VERSION ""

NS_ :

BS_:

BU_:

CM_ "(*  NOTICE: This is a sample DBC file for educational purposes only. It is not  intended for use in any production or commercial application. The content  of this file is based on the J1939 DBC format, which is a standard for  communication between electronic control units (ECUs) in heavy-duty  vehicles. The J1939 DBC format is a proprietary standard developed by the  Society of Automotive Engineers (SAE) and is subject to copyright and  licensing restrictions.";

BO_ 2565935153 B2: 8 Vector__XXX
 SG_ B2_Brake_Switch_2 : 16|2@1+ (1,0) [0|3] "" Vector__XXX
 SG_ B2_Demanded_Brake_Pres : 0|16@1+ (0.1,0) [0|0] "kPa" Vector__XXX

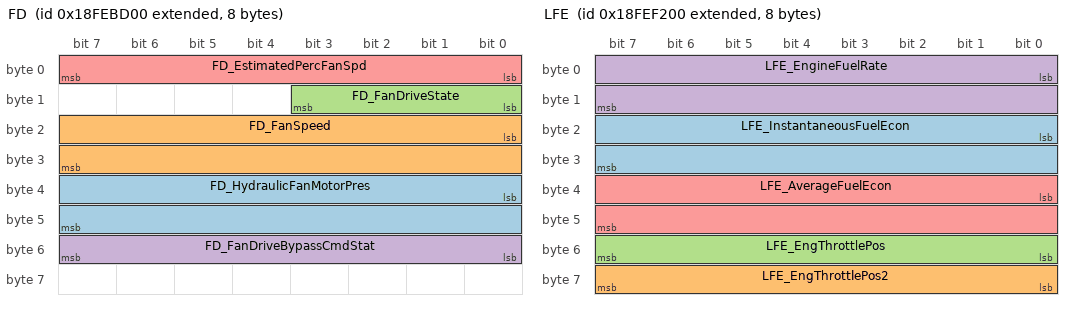
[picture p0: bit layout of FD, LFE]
BO_ 2566831360 FD: 8 Vector__XXX
 SG_ FD_HydraulicFanMotorPres : 32|16@1+ (0.5,0) [0|32127.5] "kPa" Vector__XXX
 SG_ FD_FanSpeed : 16|16@1+ (0.125,0) [0|8031.75] "rpm" Vector__XXX
 SG_ FD_FanDriveState : 8|4@1+ (1,0) [0|15] "bit" Vector__XXX
 SG_ FD_FanDriveBypassCmdStat : 48|8@1+ (0.4,0) [0|100] "%" Vector__XXX
 SG_ FD_EstimatedPercFanSpd : 0|8@1+ (0.4,0) [0|100] "%" Vector__XXX

BO_ 2566719744 HRLCF: 8 Vector__XXX
 SG_ HRLCF_EngineTripFuelHighRes : 0|32@1+ (0.001,0) [0|4211081.215] "L" Vector__XXX
 SG_ HRLCF_EngineTotalFuelUsedHighRes : 32|32@1+ (0.001,0) [0|4211081.215] "L" Vector__XXX

BO_ 2566842624 LFC: 8 Vector__XXX
 SG_ LFC_EngineTripFuel : 0|32@1+ (0.5,0) [0|2105540607.5] "L" Vector__XXX
 SG_ LFC_EngineTotalFuelUsed : 32|32@1+ (0.5,0) [0|2105540607.5] "L" Vector__XXX

BO_ 2566844928 LFE: 8 Vector__XXX
 SG_ LFE_InstantaneousFuelEcon : 16|16@1+ (0.001953125,0) [0|125.5] "km/l" Vector__XXX
 SG_ LFE_EngThrottlePos2 : 56|8@1+ (0.4,0) [0|100] "%" Vector__XXX
 SG_ LFE_EngThrottlePos : 48|8@1+ (0.4,0) [0|100] "%" Vector__XXX
 SG_ LFE_EngineFuelRate : 0|16@1+ (0.05,0) [0|3212.75] "L/h" Vector__XXX
 SG_ LFE_AverageFuelEcon : 32|16@1+ (0.001953125,0) [0|125.5] "km/l" Vector__XXX

BO_ 2566832384 VDHR: 8 Vector__XXX
 SG_ VDHR_TotalVehicleDistance : 0|32@1+ (5,0) [0|21055406] "m" Vector__XXX
 SG_ VDHR_TotalTripDistance : 32|32@1+ (5,0) [0|21055406] "m" Vector__XXX

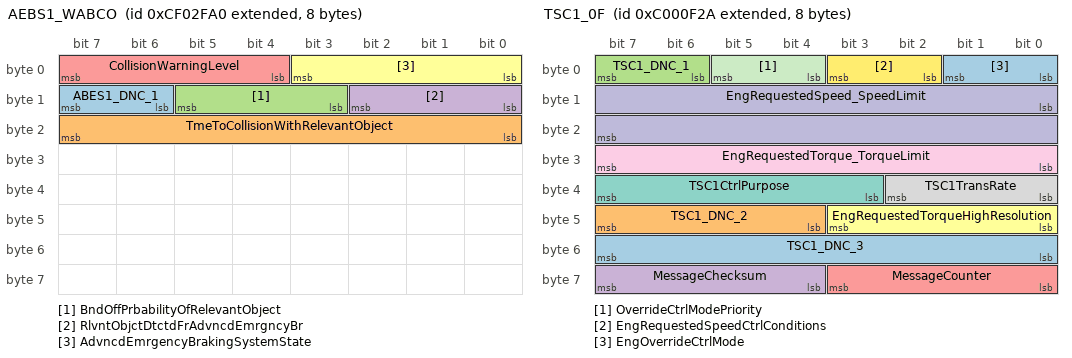
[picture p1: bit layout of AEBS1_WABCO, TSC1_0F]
BO_ 2364551072 AEBS1_WABCO: 8 Vector__XXX
 SG_ ABES1_DNC_1 : 14|2@1+ (1,0) [0|3] "" Vector__XXX
 SG_ TmeToCollisionWithRelevantObject : 16|8@1+ (0.05,0) [0|12.5] "s" Vector__XXX
 SG_ BndOffPrbabilityOfRelevantObject : 11|3@1+ (1,0) [0|7] "" Vector__XXX
 SG_ RlvntObjctDtctdFrAdvncdEmrgncyBr : 8|3@1+ (1,0) [0|7] "" Vector__XXX
 SG_ CollisionWarningLevel : 4|4@1+ (1,0) [0|15] "" Vector__XXX
 SG_ AdvncdEmrgencyBrakingSystemState : 0|4@1+ (1,0) [0|15] "" Vector__XXX

BO_ 2365518080 CCVS1_FW: 8 Vector__XXX
 SG_ EngShutdownOverrideSwitch : 62|2@1+ (1,0) [0|3] "" Vector__XXX
 SG_ EngTestModeSwitch : 60|2@1+ (1,0) [0|3] "" Vector__XXX
 SG_ EngIdleDecrementSwitch : 58|2@1+ (1,0) [0|3] "" Vector__XXX
 SG_ EngIdleIncrementSwitch : 56|2@1+ (1,0) [0|3] "" Vector__XXX
 SG_ CruiseCtrlStates : 53|3@1+ (1,0) [0|7] "" Vector__XXX
 SG_ PTOGovernorState : 48|5@1+ (1,0) [0|31] "" Vector__XXX
 SG_ CruiseCtrlSetSpeed : 40|8@1+ (1,0) [0|250] "km/h" Vector__XXX
 SG_ CruiseCtrlAccelerateSwitch : 38|2@1+ (1,0) [0|3] "" Vector__XXX
 SG_ CruiseCtrlResumeSwitch : 36|2@1+ (1,0) [0|3] "" Vector__XXX
 SG_ CruiseCtrlCoastSwitch : 34|2@1+ (1,0) [0|3] "" Vector__XXX
 SG_ CruiseCtrlSetSwitch : 32|2@1+ (1,0) [0|3] "" Vector__XXX
 SG_ ClutchSwitch : 30|2@1+ (1,0) [0|3] "" Vector__XXX
 SG_ BrakeSwitch : 28|2@1+ (1,0) [0|3] "" Vector__XXX
 SG_ CruiseCtrlEnableSwitch : 26|2@1+ (1,0) [0|3] "" Vector__XXX
 SG_ CruiseCtrlActive : 24|2@1+ (1,0) [0|3] "" Vector__XXX
 SG_ WheelBasedVehicleSpeed : 8|16@1+ (0.00390625,0) [0|250.996] "km/h" Vector__XXX
 SG_ ParkBrakeReleaseInhibitRq : 6|2@1+ (1,0) [0|3] "" Vector__XXX
 SG_ CruiseCtrlPauseSwitch : 4|2@1+ (1,0) [0|3] "" Vector__XXX
 SG_ ParkingBrakeSwitch : 2|2@1+ (1,0) [0|3] "" Vector__XXX
 SG_ TwoSpeedAxleSwitch : 0|2@1+ (1,0) [0|3] "" Vector__XXX

BO_ 2348814122 TSC1_0F: 8 Vector__XXX
 SG_ TSC1_DNC_3 : 48|8@1+ (1,0) [0|255] "" Vector__XXX
 SG_ TSC1_DNC_2 : 44|4@1+ (1,0) [0|15] "" Vector__XXX
 SG_ TSC1_DNC_1 : 6|2@1+ (1,0) [0|3] "" Vector__XXX
 SG_ MessageChecksum : 60|4@1+ (1,0) [0|15] "" Vector__XXX
 SG_ MessageCounter : 56|4@1+ (1,0) [0|15] "" Vector__XXX
 SG_ EngRequestedTorqueHighResolution : 40|4@1+ (0.125,0) [0|1.875] "%" Vector__XXX
 SG_ TSC1CtrlPurpose : 35|5@1+ (1,0) [0|31] "" Vector__XXX
 SG_ TSC1TransRate : 32|3@1+ (1,0) [0|7] "" Vector__XXX
 SG_ EngRequestedTorque_TorqueLimit : 24|8@1+ (1,-125) [-125|125] "%" Vector__XXX
 SG_ EngRequestedSpeed_SpeedLimit : 8|16@1+ (0.125,0) [0|8031.875] "rpm" Vector__XXX
 SG_ OverrideCtrlModePriority : 4|2@1+ (1,0) [0|3] "" Vector__XXX
 SG_ EngRequestedSpeedCtrlConditions : 2|2@1+ (1,0) [0|3] "" Vector__XXX
 SG_ EngOverrideCtrlMode : 0|2@1+ (1,0) [0|3] "" Vector__XXX

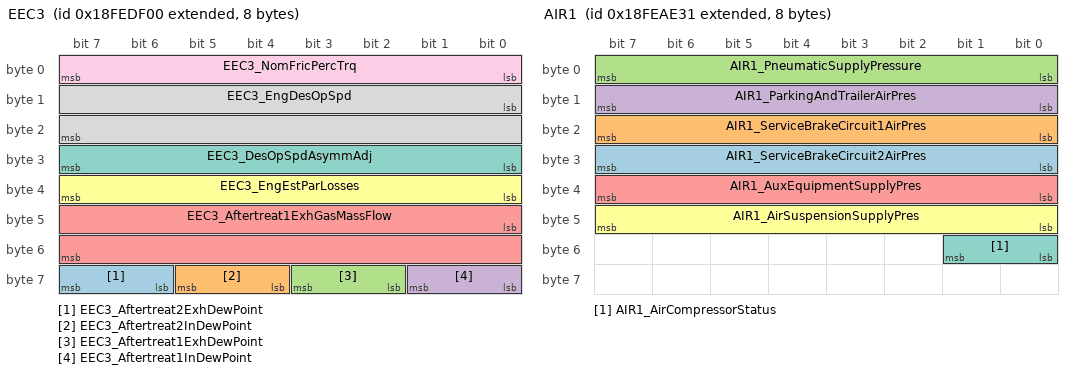
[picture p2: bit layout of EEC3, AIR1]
BO_ 2566840064 EEC3: 8 Vector__XXX
 SG_ EEC3_Aftertreat2ExhDewPoint : 62|2@1+ (1,0) [0|3] "bit" Vector__XXX
 SG_ EEC3_Aftertreat2InDewPoint : 60|2@1+ (1,0) [0|3] "bit" Vector__XXX
 SG_ EEC3_Aftertreat1ExhDewPoint : 58|2@1+ (1,0) [0|3] "bit" Vector__XXX
 SG_ EEC3_Aftertreat1InDewPoint : 56|2@1+ (1,0) [0|3] "bit" Vector__XXX
 SG_ EEC3_Aftertreat1ExhGasMassFlow : 40|16@1+ (0.2,0) [0|12851] "kg/h" Vector__XXX
 SG_ EEC3_EngEstParLosses : 32|8@1+ (1,-125) [-125|125] "%" Vector__XXX
 SG_ EEC3_DesOpSpdAsymmAdj : 24|8@1+ (1,0) [0|250] "-" Vector__XXX
 SG_ EEC3_EngDesOpSpd : 8|16@1+ (0.125,0) [0|8031.875] "rpm" Vector__XXX
 SG_ EEC3_NomFricPercTrq : 0|8@1+ (1,-125) [-125|125] "%" Vector__XXX

BO_ 2566827569 AIR1: 8 Vector__XXX
 SG_ AIR1_ServiceBrakeCircuit2AirPres : 24|8@1+ (1.1603,0) [0|290] "psi" Vector__XXX
 SG_ AIR1_ServiceBrakeCircuit1AirPres : 16|8@1+ (1.1603,0) [0|290] "psi" Vector__XXX
 SG_ AIR1_PneumaticSupplyPressure : 0|8@1+ (1.1603,0) [0|290] "psi" Vector__XXX
 SG_ AIR1_ParkingAndTrailerAirPres : 8|8@1+ (1.1603,0) [0|290] "psi" Vector__XXX
 SG_ AIR1_AuxEquipmentSupplyPres : 32|8@1+ (1.1603,0) [0|290] "psi" Vector__XXX
 SG_ AIR1_AirSuspensionSupplyPres : 40|8@1+ (1.1603,0) [0|290] "psi" Vector__XXX
 SG_ AIR1_AirCompressorStatus : 48|2@1+ (1,0) [0|3] "bit" Vector__XXX

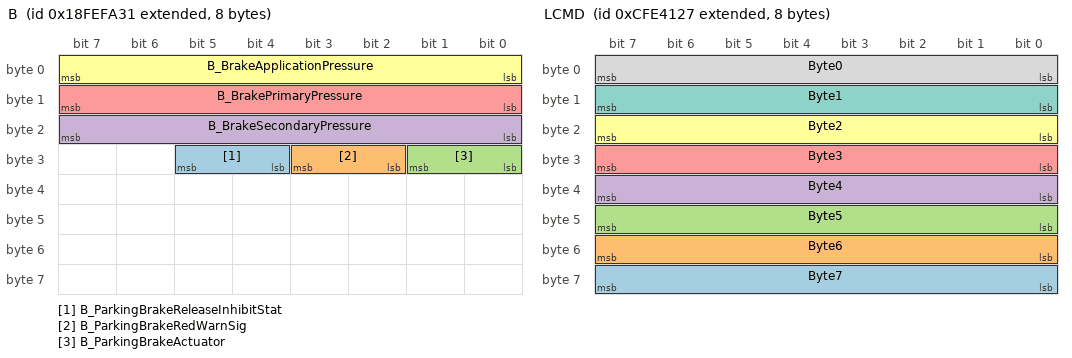
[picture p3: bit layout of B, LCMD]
BO_ 2566847025 B: 8 Vector__XXX
 SG_ B_ParkingBrakeReleaseInhibitStat : 28|2@1+ (1,0) [0|3] "bit" Vector__XXX
 SG_ B_ParkingBrakeRedWarnSig : 26|2@1+ (1,0) [0|3] "bit" Vector__XXX
 SG_ B_ParkingBrakeActuator : 24|2@1+ (1,0) [0|3] "bit" Vector__XXX
 SG_ B_BrakeSecondaryPressure : 16|8@1+ (4,0) [0|1000] "kPa" Vector__XXX
 SG_ B_BrakePrimaryPressure : 8|8@1+ (4,0) [0|1000] "kPa" Vector__XXX
 SG_ B_BrakeApplicationPressure : 0|8@1+ (4,0) [0|1000] "kPa" Vector__XXX

BO_ 2365473063 LCMD: 8 Vector__XXX
 SG_ Byte7 : 56|8@1+ (1,0) [0|255] "" Vector__XXX
 SG_ Byte6 : 48|8@1+ (1,0) [0|255] "" Vector__XXX
 SG_ Byte5 : 40|8@1+ (1,0) [0|255] "" Vector__XXX
 SG_ Byte4 : 32|8@1+ (1,0) [0|255] "" Vector__XXX
 SG_ Byte3 : 24|8@1+ (1,0) [0|255] "" Vector__XXX
 SG_ Byte2 : 16|8@1+ (1,0) [0|255] "" Vector__XXX
 SG_ Byte1 : 8|8@1+ (1,0) [0|255] "" Vector__XXX
 SG_ Byte0 : 0|8@1+ (1,0) [0|255] "" Vector__XXX

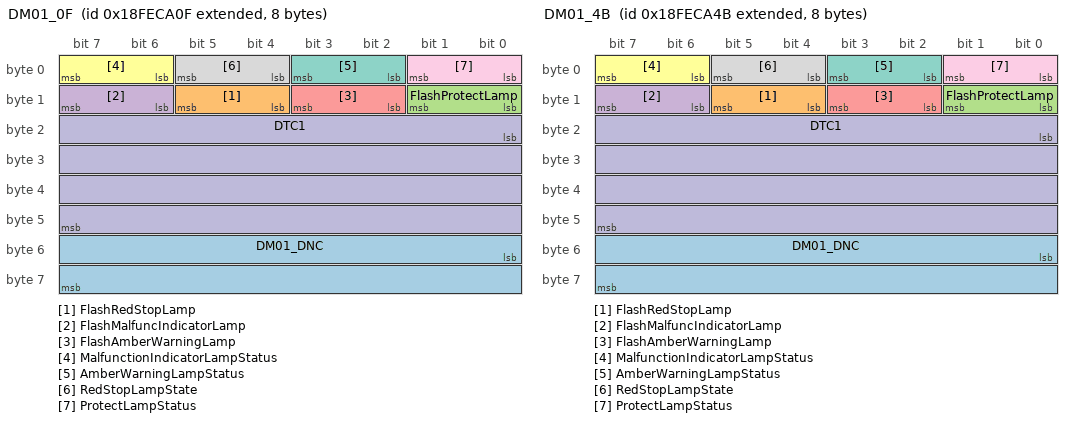
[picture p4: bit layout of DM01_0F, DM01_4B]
BO_ 2566834703 DM01_0F: 8 Vector__XXX
 SG_ DM01_DNC : 48|16@1+ (1,0) [0|0] "" Vector__XXX
 SG_ FlashRedStopLamp : 12|2@1+ (1,0) [0|3] "" Vector__XXX
 SG_ FlashProtectLamp : 8|2@1+ (1,0) [0|3] "" Vector__XXX
 SG_ FlashMalfuncIndicatorLamp : 14|2@1+ (1,0) [0|3] "" Vector__XXX
 SG_ FlashAmberWarningLamp : 10|2@1+ (1,0) [0|3] "" Vector__XXX
 SG_ MalfunctionIndicatorLampStatus : 6|2@1+ (1,0) [0|3] "" Vector__XXX
 SG_ AmberWarningLampStatus : 2|2@1+ (1,0) [0|3] "" Vector__XXX
 SG_ RedStopLampState : 4|2@1+ (1,0) [0|3] "" Vector__XXX
 SG_ ProtectLampStatus : 0|2@1+ (1,0) [0|3] "" Vector__XXX
 SG_ DTC1 : 16|32@1+ (1,0) [0|4294967295] "" Vector__XXX

BO_ 2566834763 DM01_4B: 8 Vector__XXX
 SG_ DM01_DNC : 48|16@1+ (1,0) [0|0] "" Vector__XXX
 SG_ FlashRedStopLamp : 12|2@1+ (1,0) [0|3] "" Vector__XXX
 SG_ FlashProtectLamp : 8|2@1+ (1,0) [0|3] "" Vector__XXX
 SG_ FlashMalfuncIndicatorLamp : 14|2@1+ (1,0) [0|3] "" Vector__XXX
 SG_ FlashAmberWarningLamp : 10|2@1+ (1,0) [0|3] "" Vector__XXX
 SG_ MalfunctionIndicatorLampStatus : 6|2@1+ (1,0) [0|3] "" Vector__XXX
 SG_ AmberWarningLampStatus : 2|2@1+ (1,0) [0|3] "" Vector__XXX
 SG_ RedStopLampState : 4|2@1+ (1,0) [0|3] "" Vector__XXX
 SG_ ProtectLampStatus : 0|2@1+ (1,0) [0|3] "" Vector__XXX
 SG_ DTC1 : 16|32@1+ (1,0) [0|4294967295] "" Vector__XXX

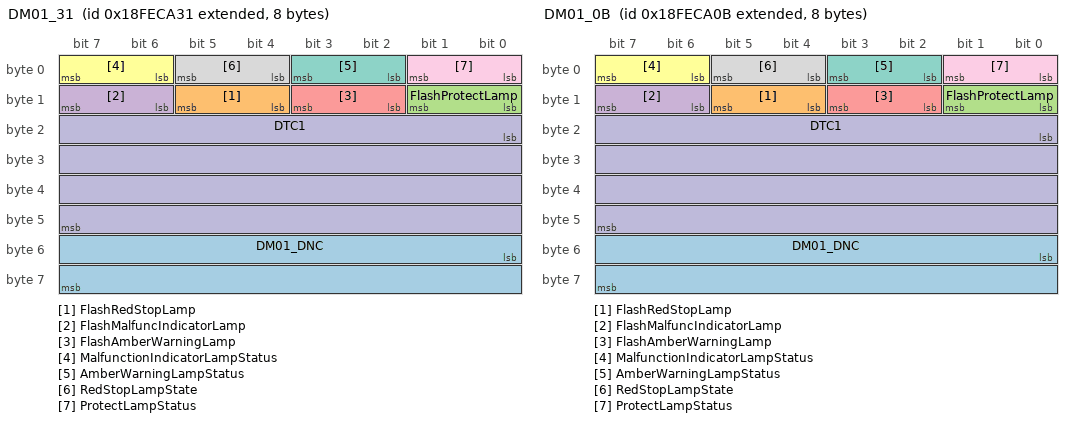
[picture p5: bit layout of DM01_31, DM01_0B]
BO_ 2566834737 DM01_31: 8 Vector__XXX
 SG_ DM01_DNC : 48|16@1+ (1,0) [0|0] "" Vector__XXX
 SG_ FlashRedStopLamp : 12|2@1+ (1,0) [0|3] "" Vector__XXX
 SG_ FlashProtectLamp : 8|2@1+ (1,0) [0|3] "" Vector__XXX
 SG_ FlashMalfuncIndicatorLamp : 14|2@1+ (1,0) [0|3] "" Vector__XXX
 SG_ FlashAmberWarningLamp : 10|2@1+ (1,0) [0|3] "" Vector__XXX
 SG_ MalfunctionIndicatorLampStatus : 6|2@1+ (1,0) [0|3] "" Vector__XXX
 SG_ AmberWarningLampStatus : 2|2@1+ (1,0) [0|3] "" Vector__XXX
 SG_ RedStopLampState : 4|2@1+ (1,0) [0|3] "" Vector__XXX
 SG_ ProtectLampStatus : 0|2@1+ (1,0) [0|3] "" Vector__XXX
 SG_ DTC1 : 16|32@1+ (1,0) [0|4294967295] "" Vector__XXX

BO_ 2566834699 DM01_0B: 8 Vector__XXX
 SG_ DM01_DNC : 48|16@1+ (1,0) [0|0] "" Vector__XXX
 SG_ FlashRedStopLamp : 12|2@1+ (1,0) [0|3] "" Vector__XXX
 SG_ FlashProtectLamp : 8|2@1+ (1,0) [0|3] "" Vector__XXX
 SG_ FlashMalfuncIndicatorLamp : 14|2@1+ (1,0) [0|3] "" Vector__XXX
 SG_ FlashAmberWarningLamp : 10|2@1+ (1,0) [0|3] "" Vector__XXX
 SG_ MalfunctionIndicatorLampStatus : 6|2@1+ (1,0) [0|3] "" Vector__XXX
 SG_ AmberWarningLampStatus : 2|2@1+ (1,0) [0|3] "" Vector__XXX
 SG_ RedStopLampState : 4|2@1+ (1,0) [0|3] "" Vector__XXX
 SG_ ProtectLampStatus : 0|2@1+ (1,0) [0|3] "" Vector__XXX
 SG_ DTC1 : 16|32@1+ (1,0) [0|4294967295] "" Vector__XXX

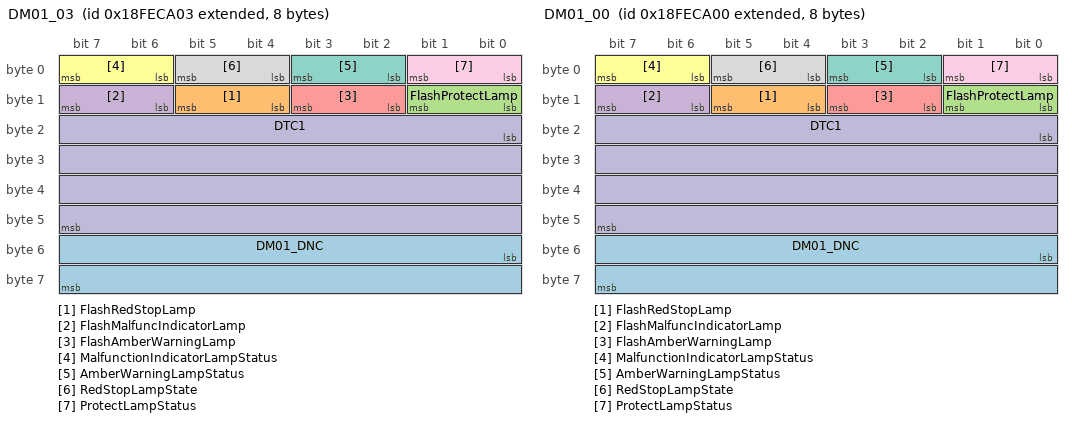
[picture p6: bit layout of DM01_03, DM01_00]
BO_ 2566834691 DM01_03: 8 Vector__XXX
 SG_ DM01_DNC : 48|16@1+ (1,0) [0|0] "" Vector__XXX
 SG_ FlashRedStopLamp : 12|2@1+ (1,0) [0|3] "" Vector__XXX
 SG_ FlashProtectLamp : 8|2@1+ (1,0) [0|3] "" Vector__XXX
 SG_ FlashMalfuncIndicatorLamp : 14|2@1+ (1,0) [0|3] "" Vector__XXX
 SG_ FlashAmberWarningLamp : 10|2@1+ (1,0) [0|3] "" Vector__XXX
 SG_ MalfunctionIndicatorLampStatus : 6|2@1+ (1,0) [0|3] "" Vector__XXX
 SG_ AmberWarningLampStatus : 2|2@1+ (1,0) [0|3] "" Vector__XXX
 SG_ RedStopLampState : 4|2@1+ (1,0) [0|3] "" Vector__XXX
 SG_ ProtectLampStatus : 0|2@1+ (1,0) [0|3] "" Vector__XXX
 SG_ DTC1 : 16|32@1+ (1,0) [0|4294967295] "" Vector__XXX

BO_ 2566834688 DM01_00: 8 Vector__XXX
 SG_ DM01_DNC : 48|16@1+ (1,0) [0|0] "" Vector__XXX
 SG_ FlashRedStopLamp : 12|2@1+ (1,0) [0|3] "" Vector__XXX
 SG_ FlashProtectLamp : 8|2@1+ (1,0) [0|3] "" Vector__XXX
 SG_ FlashMalfuncIndicatorLamp : 14|2@1+ (1,0) [0|3] "" Vector__XXX
 SG_ FlashAmberWarningLamp : 10|2@1+ (1,0) [0|3] "" Vector__XXX
 SG_ MalfunctionIndicatorLampStatus : 6|2@1+ (1,0) [0|3] "" Vector__XXX
 SG_ AmberWarningLampStatus : 2|2@1+ (1,0) [0|3] "" Vector__XXX
 SG_ RedStopLampState : 4|2@1+ (1,0) [0|3] "" Vector__XXX
 SG_ ProtectLampStatus : 0|2@1+ (1,0) [0|3] "" Vector__XXX
 SG_ DTC1 : 16|32@1+ (1,0) [0|4294967295] "" Vector__XXX

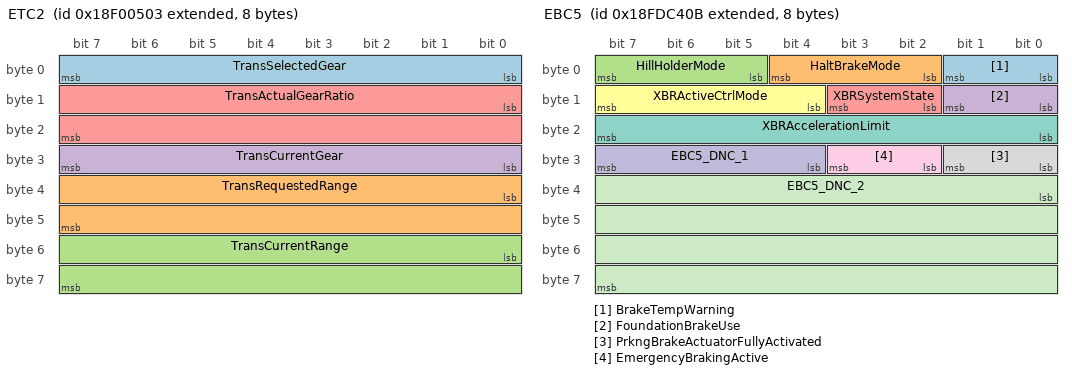
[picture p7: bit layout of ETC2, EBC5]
BO_ 2565866755 ETC2: 8 Vector__XXX
 SG_ TransSelectedGear : 0|8@1+ (1,-125) [-125|125] "" Vector__XXX
 SG_ TransRequestedRange : 32|16@1+ (1,0) [0|255] "" Vector__XXX
 SG_ TransCurrentRange : 48|16@1+ (1,0) [0|255] "" Vector__XXX
 SG_ TransCurrentGear : 24|8@1+ (1,-125) [-125|125] "" Vector__XXX
 SG_ TransActualGearRatio : 8|16@1+ (0.001,0) [0|64.255] "" Vector__XXX

BO_ 2566844721 CCVS1: 8 Vector__XXX
 SG_ EngShutdownOverrideSwitch : 62|2@1+ (1,0) [0|3] "" Vector__XXX
 SG_ EngTestModeSwitch : 60|2@1+ (1,0) [0|3] "" Vector__XXX
 SG_ EngIdleDecrementSwitch : 58|2@1+ (1,0) [0|3] "" Vector__XXX
 SG_ EngIdleIncrementSwitch : 56|2@1+ (1,0) [0|3] "" Vector__XXX
 SG_ CruiseCtrlStates : 53|3@1+ (1,0) [0|7] "" Vector__XXX
 SG_ PTOGovernorState : 48|5@1+ (1,0) [0|31] "" Vector__XXX
 SG_ CruiseCtrlSetSpeed : 40|8@1+ (1,0) [0|250] "km/h" Vector__XXX
 SG_ CruiseCtrlAccelerateSwitch : 38|2@1+ (1,0) [0|3] "" Vector__XXX
 SG_ CruiseCtrlResumeSwitch : 36|2@1+ (1,0) [0|3] "" Vector__XXX
 SG_ CruiseCtrlCoastSwitch : 34|2@1+ (1,0) [0|3] "" Vector__XXX
 SG_ CruiseCtrlSetSwitch : 32|2@1+ (1,0) [0|3] "" Vector__XXX
 SG_ ClutchSwitch : 30|2@1+ (1,0) [0|3] "" Vector__XXX
 SG_ BrakeSwitch : 28|2@1+ (1,0) [0|3] "" Vector__XXX
 SG_ CruiseCtrlEnableSwitch : 26|2@1+ (1,0) [0|3] "" Vector__XXX
 SG_ CruiseCtrlActive : 24|2@1+ (1,0) [0|3] "" Vector__XXX
 SG_ WheelBasedVehicleSpeed : 8|16@1+ (0.00390625,0) [0|250.996] "km/h" Vector__XXX
 SG_ ParkBrakeReleaseInhibitRq : 6|2@1+ (1,0) [0|3] "" Vector__XXX
 SG_ CruiseCtrlPauseSwitch : 4|2@1+ (1,0) [0|3] "" Vector__XXX
 SG_ ParkingBrakeSwitch : 2|2@1+ (1,0) [0|3] "" Vector__XXX
 SG_ TwoSpeedAxleSwitch : 0|2@1+ (1,0) [0|3] "" Vector__XXX

BO_ 2565865739 EBC1: 8 Vector__XXX
 SG_ ASREngCtrlActive : 0|2@1+ (1,0) [0|3] "" Vector__XXX
 SG_ ASRBrakeCtrlActive : 2|2@1+ (1,0) [0|3] "" Vector__XXX
 SG_ AntiLockBrakingActive : 4|2@1+ (1,0) [0|3] "" Vector__XXX
 SG_ EBSBrakeSwitch : 6|2@1+ (1,0) [0|3] "" Vector__XXX
 SG_ BrakePedalPos : 8|8@1+ (0.4,0) [0|100] "%" Vector__XXX
 SG_ ABSOffroadSwitch : 16|2@1+ (1,0) [0|3] "" Vector__XXX
 SG_ ASROffroadSwitch : 18|2@1+ (1,0) [0|3] "" Vector__XXX
 SG_ ASRHillHolderSwitch : 20|2@1+ (1,0) [0|3] "" Vector__XXX
 SG_ TractionCtrlOverrideSwitch : 22|2@1+ (1,0) [0|3] "" Vector__XXX
 SG_ AccelInterlockSwitch : 24|2@1+ (1,0) [0|3] "" Vector__XXX
 SG_ EngDerateSwitch : 26|2@1+ (1,0) [0|3] "" Vector__XXX
 SG_ EngAuxShutdownSwitch : 28|2@1+ (1,0) [0|3] "" Vector__XXX
 SG_ RemoteAccelEnableSwitch : 30|2@1+ (1,0) [0|3] "" Vector__XXX
 SG_ EngRetarderSelection : 32|8@1+ (0.4,0) [0|100] "%" Vector__XXX
 SG_ ABSFullyOperational : 40|2@1+ (1,0) [0|3] "" Vector__XXX
 SG_ EBSRedWarningSignal : 42|2@1+ (1,0) [0|3] "" Vector__XXX
 SG_ ABS_EBSAmberWarningSignal : 44|2@1+ (1,0) [0|3] "" Vector__XXX
 SG_ ATC_ASRInformationSignal : 46|2@1+ (1,0) [0|3] "" Vector__XXX
 SG_ SrcAddrssOfCntrllngDvcFrBrkeCtrl : 48|8@1+ (1,0) [0|253] "" Vector__XXX
 SG_ HaltBrakeSwitch : 58|2@1+ (1,0) [0|3] "" Vector__XXX
 SG_ TrailerABSStatus : 60|2@1+ (1,0) [0|3] "" Vector__XXX
 SG_ TrctrMntdTrailerABSWarningSignal : 62|2@1+ (1,0) [0|3] "" Vector__XXX
 SG_ EBC1_DNC_1 : 56|2@1+ (1,0) [0|0] "" Vector__XXX

BO_ 2566767627 EBC5: 8 Vector__XXX
 SG_ BrakeTempWarning : 0|2@1+ (1,0) [0|3] "" Vector__XXX
 SG_ HaltBrakeMode : 2|3@1+ (1,0) [0|7] "" Vector__XXX
 SG_ HillHolderMode : 5|3@1+ (1,0) [0|7] "" Vector__XXX
 SG_ FoundationBrakeUse : 8|2@1+ (1,0) [0|3] "" Vector__XXX
 SG_ XBRSystemState : 10|2@1+ (1,0) [0|3] "" Vector__XXX
 SG_ XBRActiveCtrlMode : 12|4@1+ (1,0) [0|15] "" Vector__XXX
 SG_ XBRAccelerationLimit : 16|8@1+ (0.1,-12.5) [-10|10] "m/s²" Vector__XXX
 SG_ PrkngBrakeActuatorFullyActivated : 24|2@1+ (1,0) [0|3] "" Vector__XXX
 SG_ EmergencyBrakingActive : 26|2@1+ (1,0) [0|3] "" Vector__XXX
 SG_ EBC5_DNC_1 : 28|4@1+ (1,0) [0|0] "" Vector__XXX
 SG_ EBC5_DNC_2 : 32|32@1+ (1,0) [0|0] "" Vector__XXX

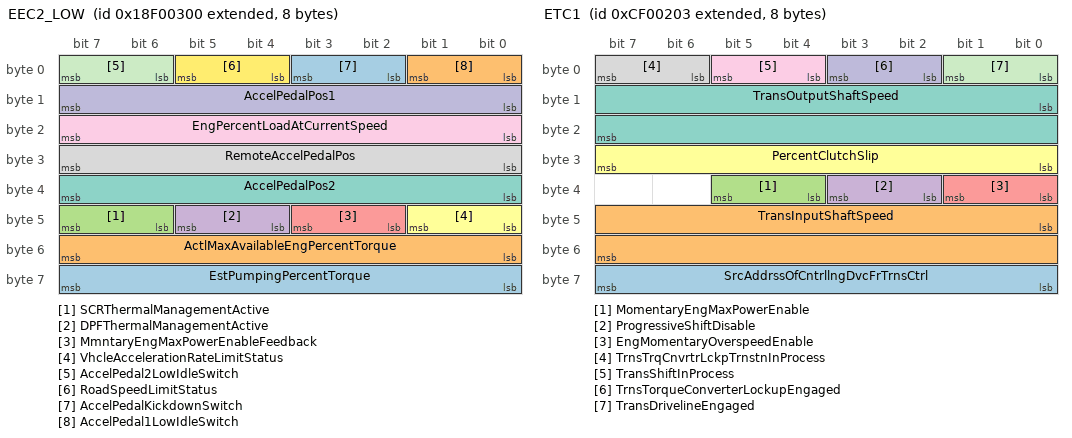
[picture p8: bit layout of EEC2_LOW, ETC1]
BO_ 2565866240 EEC2_LOW: 8 Vector__XXX
 SG_ EstPumpingPercentTorque : 56|8@1+ (1,-125) [-125|125] "%" Vector__XXX
 SG_ ActlMaxAvailableEngPercentTorque : 48|8@1+ (0.4,0) [0|100] "%" Vector__XXX
 SG_ SCRThermalManagementActive : 46|2@1+ (1,0) [0|3] "" Vector__XXX
 SG_ DPFThermalManagementActive : 44|2@1+ (1,0) [0|3] "" Vector__XXX
 SG_ MmntaryEngMaxPowerEnableFeedback : 42|2@1+ (1,0) [0|3] "" Vector__XXX
 SG_ VhcleAccelerationRateLimitStatus : 40|2@1+ (1,0) [0|3] "" Vector__XXX
 SG_ AccelPedalPos2 : 32|8@1+ (0.4,0) [0|100] "%" Vector__XXX
 SG_ RemoteAccelPedalPos : 24|8@1+ (0.4,0) [0|100] "%" Vector__XXX
 SG_ EngPercentLoadAtCurrentSpeed : 16|8@1+ (1,0) [0|125] "%" Vector__XXX
 SG_ AccelPedalPos1 : 8|8@1+ (0.4,0) [0|100] "%" Vector__XXX
 SG_ AccelPedal2LowIdleSwitch : 6|2@1+ (1,0) [0|3] "" Vector__XXX
 SG_ RoadSpeedLimitStatus : 4|2@1+ (1,0) [0|3] "" Vector__XXX
 SG_ AccelPedalKickdownSwitch : 2|2@1+ (1,0) [0|3] "" Vector__XXX
 SG_ AccelPedal1LowIdleSwitch : 0|2@1+ (1,0) [0|3] "" Vector__XXX

BO_ 2364539395 ETC1: 8 Vector__XXX
 SG_ SrcAddrssOfCntrllngDvcFrTrnsCtrl : 56|8@1+ (1,0) [0|253] "" Vector__XXX
 SG_ TransInputShaftSpeed : 40|16@1+ (0.125,0) [0|8031.875] "rpm" Vector__XXX
 SG_ MomentaryEngMaxPowerEnable : 36|2@1+ (1,0) [0|3] "" Vector__XXX
 SG_ ProgressiveShiftDisable : 34|2@1+ (1,0) [0|3] "" Vector__XXX
 SG_ EngMomentaryOverspeedEnable : 32|2@1+ (1,0) [0|3] "" Vector__XXX
 SG_ PercentClutchSlip : 24|8@1+ (0.4,0) [0|100] "%" Vector__XXX
 SG_ TransOutputShaftSpeed : 8|16@1+ (0.125,0) [0|8031.875] "rpm" Vector__XXX
 SG_ TrnsTrqCnvrtrLckpTrnstnInProcess : 6|2@1+ (1,0) [0|3] "" Vector__XXX
 SG_ TransShiftInProcess : 4|2@1+ (1,0) [0|3] "" Vector__XXX
 SG_ TrnsTorqueConverterLockupEngaged : 2|2@1+ (1,0) [0|3] "" Vector__XXX
 SG_ TransDrivelineEngaged : 0|2@1+ (1,0) [0|3] "" Vector__XXX

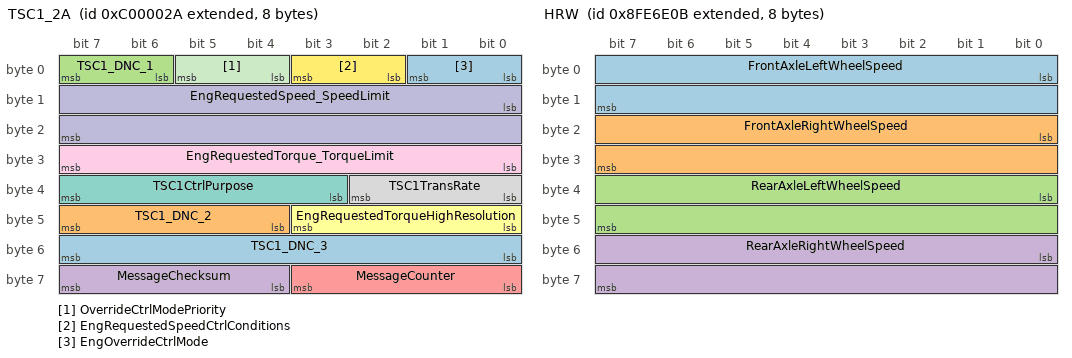
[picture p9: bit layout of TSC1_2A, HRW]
BO_ 2348810282 TSC1_2A: 8 Vector__XXX
 SG_ TSC1_DNC_3 : 48|8@1+ (1,0) [0|255] "" Vector__XXX
 SG_ TSC1_DNC_2 : 44|4@1+ (1,0) [0|15] "" Vector__XXX
 SG_ TSC1_DNC_1 : 6|2@1+ (1,0) [0|3] "" Vector__XXX
 SG_ MessageChecksum : 60|4@1+ (1,0) [0|15] "" Vector__XXX
 SG_ MessageCounter : 56|4@1+ (1,0) [0|15] "" Vector__XXX
 SG_ EngRequestedTorqueHighResolution : 40|4@1+ (0.125,0) [0|1.875] "%" Vector__XXX
 SG_ TSC1CtrlPurpose : 35|5@1+ (1,0) [0|31] "" Vector__XXX
 SG_ TSC1TransRate : 32|3@1+ (1,0) [0|7] "" Vector__XXX
 SG_ EngRequestedTorque_TorqueLimit : 24|8@1+ (1,-125) [-125|125] "%" Vector__XXX
 SG_ EngRequestedSpeed_SpeedLimit : 8|16@1+ (0.125,0) [0|8031.875] "rpm" Vector__XXX
 SG_ OverrideCtrlModePriority : 4|2@1+ (1,0) [0|3] "" Vector__XXX
 SG_ EngRequestedSpeedCtrlConditions : 2|2@1+ (1,0) [0|3] "" Vector__XXX
 SG_ EngOverrideCtrlMode : 0|2@1+ (1,0) [0|3] "" Vector__XXX

BO_ 2298375691 HRW: 8 Vector__XXX
 SG_ FrontAxleLeftWheelSpeed : 0|16@1+ (0.00390625,0) [0|250.996] "km/h" Vector__XXX
 SG_ FrontAxleRightWheelSpeed : 16|16@1+ (0.00390625,0) [0|250.996] "km/h" Vector__XXX
 SG_ RearAxleLeftWheelSpeed : 32|16@1+ (0.00390625,0) [0|250.996] "km/h" Vector__XXX
 SG_ RearAxleRightWheelSpeed : 48|16@1+ (0.00390625,0) [0|250.996] "km/h" Vector__XXX

BO_ 2565475114 RQST: 3 Vector__XXX
 SG_ ParameterGroupNumber : 0|24@1+ (1,0) [0|16777215] "" Vector__XXX

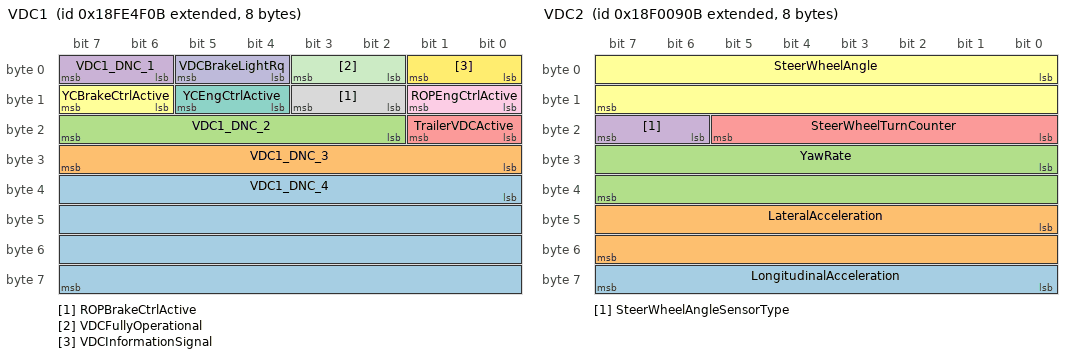
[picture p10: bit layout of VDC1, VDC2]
BO_ 2566803211 VDC1: 8 Vector__XXX
 SG_ VDC1_DNC_4 : 32|32@1+ (1,0) [0|0] "" Vector__XXX
 SG_ VDC1_DNC_3 : 24|8@1+ (1,0) [0|0] "" Vector__XXX
 SG_ VDC1_DNC_2 : 18|6@1+ (1,0) [0|0] "" Vector__XXX
 SG_ VDC1_DNC_1 : 6|2@1+ (1,0) [0|0] "" Vector__XXX
 SG_ TrailerVDCActive : 16|2@1+ (1,0) [0|3] "" Vector__XXX
 SG_ YCBrakeCtrlActive : 14|2@1+ (1,0) [0|3] "" Vector__XXX
 SG_ YCEngCtrlActive : 12|2@1+ (1,0) [0|3] "" Vector__XXX
 SG_ ROPBrakeCtrlActive : 10|2@1+ (1,0) [0|3] "" Vector__XXX
 SG_ ROPEngCtrlActive : 8|2@1+ (1,0) [0|3] "" Vector__XXX
 SG_ VDCBrakeLightRq : 4|2@1+ (1,0) [0|3] "" Vector__XXX
 SG_ VDCFullyOperational : 2|2@1+ (1,0) [0|3] "" Vector__XXX
 SG_ VDCInformationSignal : 0|2@1+ (1,0) [0|3] "" Vector__XXX

BO_ 2565867787 VDC2: 8 Vector__XXX
 SG_ LongitudinalAcceleration : 56|8@1+ (0.1,-12.5) [-12.5|12.5] "m/s²" Vector__XXX
 SG_ LateralAcceleration : 40|16@1+ (0.00048828125,-15.687) [-15.687|15.687] "m/s²" Vector__XXX
 SG_ YawRate : 24|16@1+ (0.0001220703125,-3.92) [-3.92|3.92] "rad/s" Vector__XXX
 SG_ SteerWheelAngleSensorType : 22|2@1+ (1,0) [0|3] "" Vector__XXX
 SG_ SteerWheelTurnCounter : 16|6@1+ (1,-32) [-10|10] "turns" Vector__XXX
 SG_ SteerWheelAngle : 0|16@1+ (0.0009765625,-31.374) [-31.374|31.374] "rad" Vector__XXX

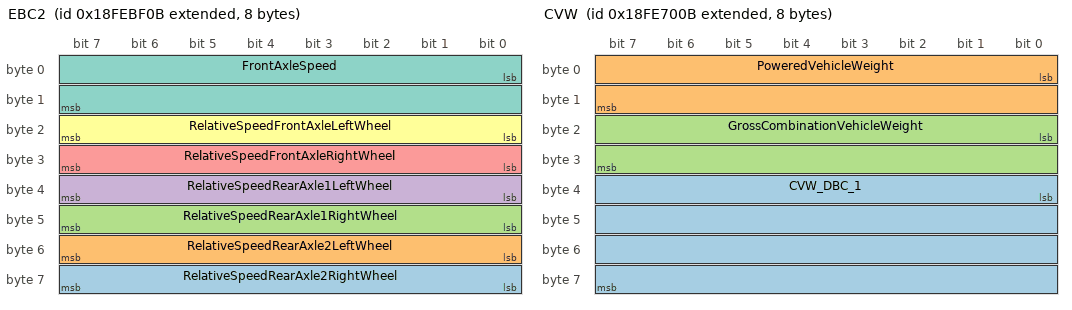
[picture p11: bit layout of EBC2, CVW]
BO_ 2566831883 EBC2: 8 Vector__XXX
 SG_ RelativeSpeedRearAxle2RightWheel : 56|8@1+ (0.0625,-7.8125) [-7.8125|7.8125] "km/h" Vector__XXX
 SG_ RelativeSpeedRearAxle2LeftWheel : 48|8@1+ (0.0625,-7.8125) [-7.8125|7.8125] "km/h" Vector__XXX
 SG_ RelativeSpeedRearAxle1RightWheel : 40|8@1+ (0.0625,-7.8125) [-7.8125|7.8125] "km/h" Vector__XXX
 SG_ RelativeSpeedRearAxle1LeftWheel : 32|8@1+ (0.0625,-7.8125) [-7.8125|7.8125] "km/h" Vector__XXX
 SG_ RelativeSpeedFrontAxleRightWheel : 24|8@1+ (0.0625,-7.8125) [-7.8125|7.8125] "km/h" Vector__XXX
 SG_ RelativeSpeedFrontAxleLeftWheel : 16|8@1+ (0.0625,-7.8125) [-7.8125|7.8125] "km/h" Vector__XXX
 SG_ FrontAxleSpeed : 0|16@1+ (0.00390625,0) [0|250.996] "km/h" Vector__XXX

BO_ 2566811659 CVW: 8 Vector__XXX
 SG_ CVW_DBC_1 : 32|32@1+ (1,0) [0|0] "" Vector__XXX
 SG_ PoweredVehicleWeight : 0|16@1+ (10,0) [0|642550] "kg" Vector__XXX
 SG_ GrossCombinationVehicleWeight : 16|16@1+ (10,0) [0|642550] "kg" Vector__XXX

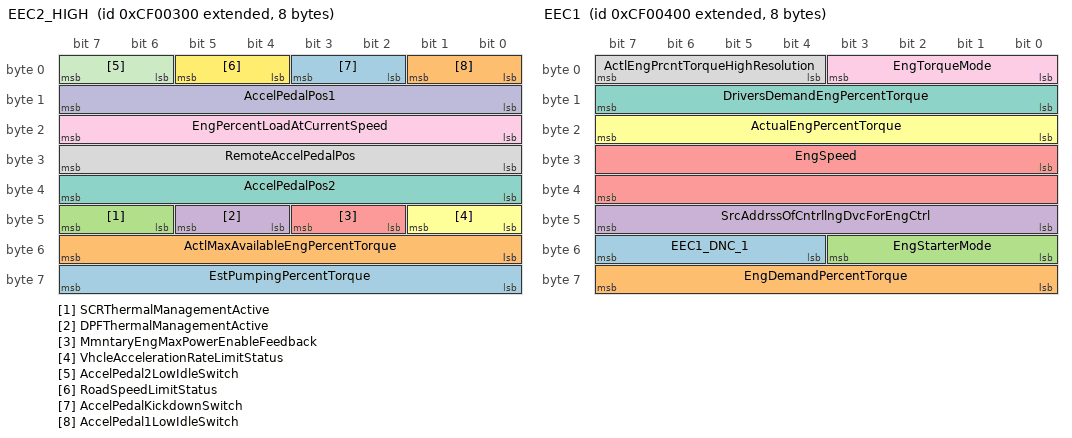
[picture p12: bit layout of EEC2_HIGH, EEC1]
BO_ 2364539648 EEC2_HIGH: 8 Vector__XXX
 SG_ EstPumpingPercentTorque : 56|8@1+ (1,-125) [-125|125] "%" Vector__XXX
 SG_ ActlMaxAvailableEngPercentTorque : 48|8@1+ (0.4,0) [0|100] "%" Vector__XXX
 SG_ SCRThermalManagementActive : 46|2@1+ (1,0) [0|3] "" Vector__XXX
 SG_ DPFThermalManagementActive : 44|2@1+ (1,0) [0|3] "" Vector__XXX
 SG_ MmntaryEngMaxPowerEnableFeedback : 42|2@1+ (1,0) [0|3] "" Vector__XXX
 SG_ VhcleAccelerationRateLimitStatus : 40|2@1+ (1,0) [0|3] "" Vector__XXX
 SG_ AccelPedalPos2 : 32|8@1+ (0.4,0) [0|100] "%" Vector__XXX
 SG_ RemoteAccelPedalPos : 24|8@1+ (0.4,0) [0|100] "%" Vector__XXX
 SG_ EngPercentLoadAtCurrentSpeed : 16|8@1+ (1,0) [0|125] "%" Vector__XXX
 SG_ AccelPedalPos1 : 8|8@1+ (0.4,0) [0|100] "%" Vector__XXX
 SG_ AccelPedal2LowIdleSwitch : 6|2@1+ (1,0) [0|3] "" Vector__XXX
 SG_ RoadSpeedLimitStatus : 4|2@1+ (1,0) [0|3] "" Vector__XXX
 SG_ AccelPedalKickdownSwitch : 2|2@1+ (1,0) [0|3] "" Vector__XXX
 SG_ AccelPedal1LowIdleSwitch : 0|2@1+ (1,0) [0|3] "" Vector__XXX

BO_ 2364539904 EEC1: 8 Vector__XXX
 SG_ EEC1_DNC_1 : 52|4@1- (1,0) [0|0] "" Vector__XXX
 SG_ EngDemandPercentTorque : 56|8@1+ (1,-125) [-125|125] "%" Vector__XXX
 SG_ EngStarterMode : 48|4@1+ (1,0) [0|15] "" Vector__XXX
 SG_ SrcAddrssOfCntrllngDvcForEngCtrl : 40|8@1+ (1,0) [0|253] "" Vector__XXX
 SG_ EngSpeed : 24|16@1+ (0.125,0) [0|8031.875] "rpm" Vector__XXX
 SG_ ActualEngPercentTorque : 16|8@1+ (1,-125) [0|125] "%" Vector__XXX
 SG_ DriversDemandEngPercentTorque : 8|8@1+ (1,-125) [0|125] "%" Vector__XXX
 SG_ ActlEngPrcntTorqueHighResolution : 4|4@1+ (0.125,0) [0|0.875] "%" Vector__XXX
 SG_ EngTorqueMode : 0|4@1+ (1,0) [0|15] "" Vector__XXX

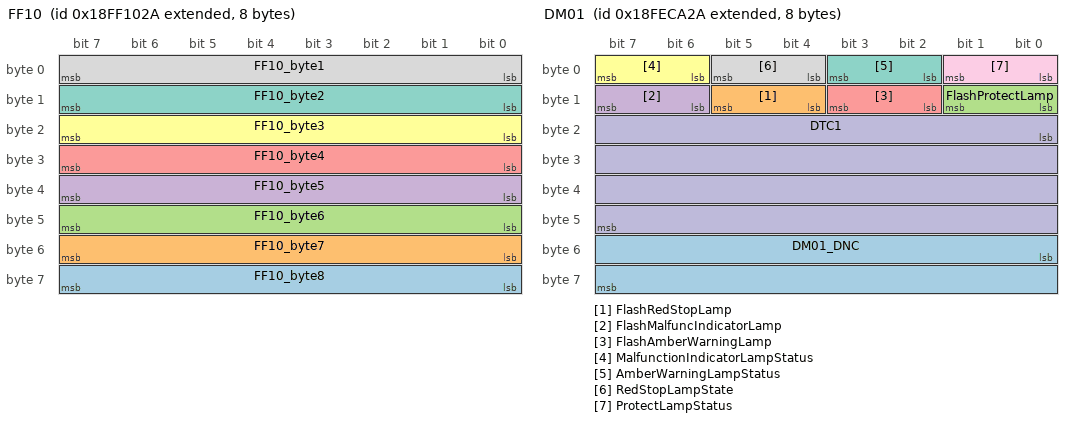
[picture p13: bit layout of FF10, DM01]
BO_ 2566852650 FF10: 8 Vector__XXX
 SG_ FF10_byte8 : 56|8@1+ (1,0) [0|255] "" Vector__XXX
 SG_ FF10_byte7 : 48|8@1+ (1,0) [0|255] "" Vector__XXX
 SG_ FF10_byte6 : 40|8@1+ (1,0) [0|255] "" Vector__XXX
 SG_ FF10_byte5 : 32|8@1+ (1,0) [0|255] "" Vector__XXX
 SG_ FF10_byte4 : 24|8@1+ (1,0) [0|255] "" Vector__XXX
 SG_ FF10_byte3 : 16|8@1+ (1,0) [0|255] "" Vector__XXX
 SG_ FF10_byte2 : 8|8@1+ (1,0) [0|255] "" Vector__XXX
 SG_ FF10_byte1 : 0|8@1+ (1,0) [0|255] "" Vector__XXX

BO_ 2566834730 DM01: 8 Vector__XXX
 SG_ DM01_DNC : 48|16@1+ (1,0) [0|0] "" Vector__XXX
 SG_ FlashRedStopLamp : 12|2@1+ (1,0) [0|3] "" Vector__XXX
 SG_ FlashProtectLamp : 8|2@1+ (1,0) [0|3] "" Vector__XXX
 SG_ FlashMalfuncIndicatorLamp : 14|2@1+ (1,0) [0|3] "" Vector__XXX
 SG_ FlashAmberWarningLamp : 10|2@1+ (1,0) [0|3] "" Vector__XXX
 SG_ MalfunctionIndicatorLampStatus : 6|2@1+ (1,0) [0|3] "" Vector__XXX
 SG_ AmberWarningLampStatus : 2|2@1+ (1,0) [0|3] "" Vector__XXX
 SG_ RedStopLampState : 4|2@1+ (1,0) [0|3] "" Vector__XXX
 SG_ ProtectLampStatus : 0|2@1+ (1,0) [0|3] "" Vector__XXX
 SG_ DTC1 : 16|32@1+ (1,0) [0|4294967295] "" Vector__XXX

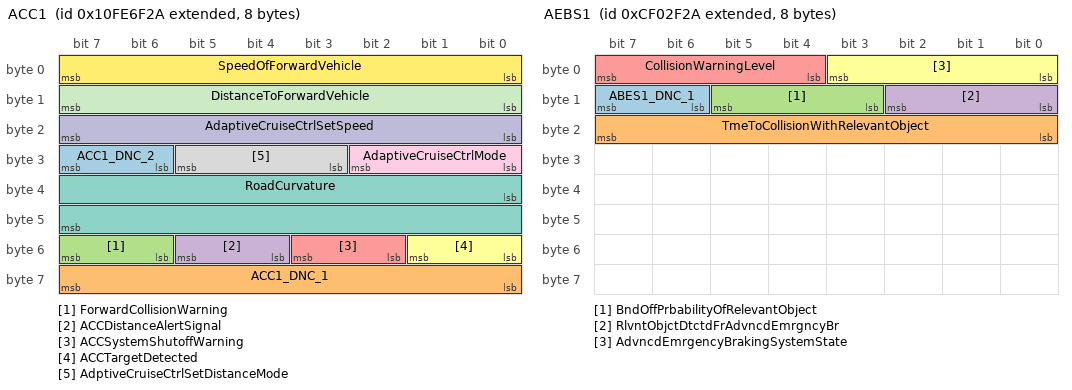
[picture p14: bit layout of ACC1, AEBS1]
BO_ 2432593706 ACC1: 8 Vector__XXX
 SG_ ACC1_DNC_2 : 30|2@1+ (1,0) [0|3] "" Vector__XXX
 SG_ ACC1_DNC_1 : 56|8@1+ (1,0) [0|255] "" Vector__XXX
 SG_ ForwardCollisionWarning : 54|2@1+ (1,0) [0|3] "" Vector__XXX
 SG_ ACCDistanceAlertSignal : 52|2@1+ (1,0) [0|3] "" Vector__XXX
 SG_ ACCSystemShutoffWarning : 50|2@1+ (1,0) [0|3] "" Vector__XXX
 SG_ ACCTargetDetected : 48|2@1+ (1,0) [0|3] "" Vector__XXX
 SG_ RoadCurvature : 32|16@1+ (0.0078125,-250) [-250|251.992] "1/km" Vector__XXX
 SG_ AdptiveCruiseCtrlSetDistanceMode : 27|3@1+ (1,0) [0|7] "" Vector__XXX
 SG_ AdaptiveCruiseCtrlMode : 24|3@1+ (1,0) [0|7] "" Vector__XXX
 SG_ AdaptiveCruiseCtrlSetSpeed : 16|8@1+ (1,0) [0|120] "km/h" Vector__XXX
 SG_ DistanceToForwardVehicle : 8|8@1+ (1,0) [0|250] "m" Vector__XXX
 SG_ SpeedOfForwardVehicle : 0|8@1+ (1,0) [0|250] "km/h" Vector__XXX

BO_ 2364550954 AEBS1: 8 Vector__XXX
 SG_ ABES1_DNC_1 : 14|2@1+ (1,0) [0|3] "" Vector__XXX
 SG_ TmeToCollisionWithRelevantObject : 16|8@1+ (0.05,0) [0|12.5] "s" Vector__XXX
 SG_ BndOffPrbabilityOfRelevantObject : 11|3@1+ (1,0) [0|7] "" Vector__XXX
 SG_ RlvntObjctDtctdFrAdvncdEmrgncyBr : 8|3@1+ (1,0) [0|7] "" Vector__XXX
 SG_ CollisionWarningLevel : 4|4@1+ (1,0) [0|15] "" Vector__XXX
 SG_ AdvncdEmrgencyBrakingSystemState : 0|4@1+ (1,0) [0|15] "" Vector__XXX

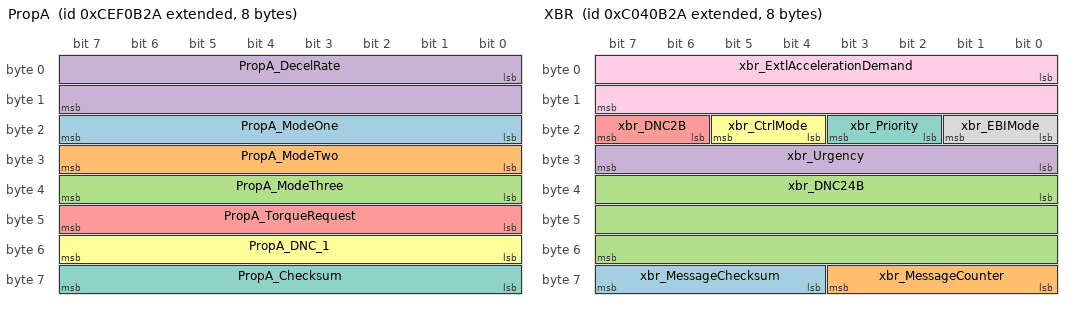
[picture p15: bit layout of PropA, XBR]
BO_ 2364476202 PropA: 8 Vector__XXX
 SG_ PropA_ModeOne : 16|8@1+ (1,0) [0|0] "" Vector__XXX
 SG_ PropA_ModeTwo : 24|8@1+ (1,0) [0|0] "" Vector__XXX
 SG_ PropA_ModeThree : 32|8@1+ (1,0) [0|0] "" Vector__XXX
 SG_ PropA_DecelRate : 0|16@1+ (1,0) [0|65535] "" Vector__XXX
 SG_ PropA_TorqueRequest : 40|8@1+ (1,-125) [0|100] "" Vector__XXX
 SG_ PropA_DNC_1 : 48|8@1+ (1,0) [0|0] "" Vector__XXX
 SG_ PropA_Checksum : 56|8@1+ (1,0) [0|255] "" Vector__XXX

BO_ 2349075242 XBR: 8 Vector__XXX
 SG_ xbr_MessageChecksum : 60|4@1+ (1,0) [0|15] "" Vector__XXX
 SG_ xbr_MessageCounter : 56|4@1+ (1,0) [0|15] "" Vector__XXX
 SG_ xbr_DNC24B : 32|24@1+ (1,0) [0|16777215] "" Vector__XXX
 SG_ xbr_Urgency : 24|8@1+ (0.4,0) [0|0] "%" Vector__XXX
 SG_ xbr_DNC2B : 22|2@1+ (1,0) [0|3] "" Vector__XXX
 SG_ xbr_CtrlMode : 20|2@1+ (1,0) [0|3] "" Vector__XXX
 SG_ xbr_Priority : 18|2@1+ (1,0) [0|3] "" Vector__XXX
 SG_ xbr_EBIMode : 16|2@1+ (1,0) [0|3] "" Vector__XXX
 SG_ xbr_ExtlAccelerationDemand : 0|16@1+ (0.000488,-15.687) [-15.687|16.29408] "m/s²" Vector__XXX

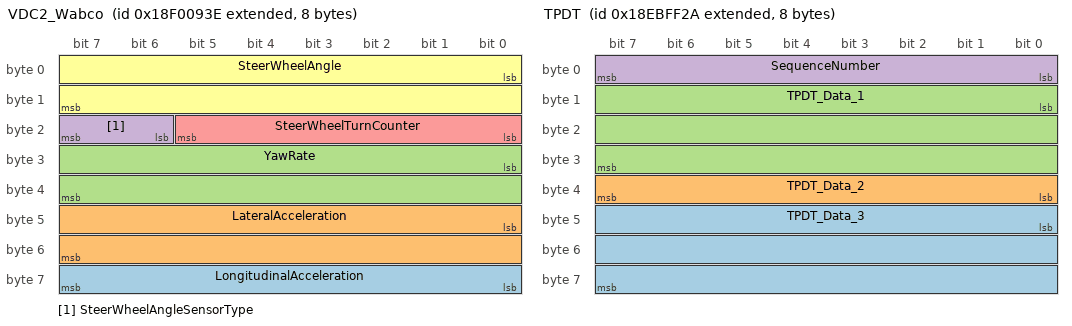
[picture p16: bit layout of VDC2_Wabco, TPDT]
BO_ 2565867838 VDC2_Wabco: 8 Vector__XXX
 SG_ LongitudinalAcceleration : 56|8@1+ (0.1,-12.5) [-12.5|12.5] "m/sÂ²" Vector__XXX
 SG_ LateralAcceleration : 40|16@1+ (0.00048828125,-15.687) [-15.687|15.687] "m/sÂ²" Vector__XXX
 SG_ YawRate : 24|16@1+ (0.0001220703125,-3.92) [-3.92|3.92] "rad/s" Vector__XXX
 SG_ SteerWheelAngleSensorType : 22|2@1+ (1,0) [0|3] "" Vector__XXX
 SG_ SteerWheelTurnCounter : 16|6@1+ (1,-32) [-10|10] "turns" Vector__XXX
 SG_ SteerWheelAngle : 0|16@1+ (0.0009765625,-31.374) [-31.374|31.374] "rad" Vector__XXX

BO_ 2565668650 TPCMxx: 8 Vector__XXX
 SG_ PGNumber : 40|24@1+ (1,0) [0|16777200] "" Vector__XXX
 SG_ MaximumNumberOfPackets m16 : 32|8@1+ (1,0) [0|255] "" Vector__XXX
 SG_ TotalNumberOfPackets m16 : 24|8@1+ (1,0) [0|255] "" Vector__XXX
 SG_ TotalMessageSize m16 : 8|16@1+ (1,0) [0|64255] "" Vector__XXX
 SG_ ControlByte M : 0|8@1+ (1,0) [0|255] "" Vector__XXX

BO_ 2565603114 TPDT: 8 Vector__XXX
 SG_ TPDT_Data_3 : 40|24@1+ (1,0) [0|4294967296] "" Vector__XXX
 SG_ TPDT_Data_2 : 32|8@1+ (1,0) [0|255] "" Vector__XXX
 SG_ TPDT_Data_1 : 8|24@1+ (1,0) [0|16777216] "" Vector__XXX
 SG_ SequenceNumber : 0|8@1+ (1,0) [0|255] "" Vector__XXX

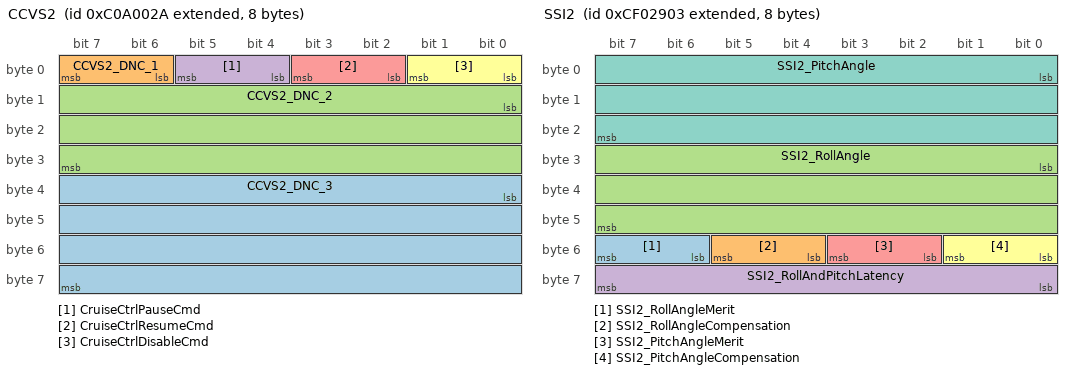
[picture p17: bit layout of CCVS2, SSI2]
BO_ 2349465642 CCVS2: 8 Vector__XXX
 SG_ CCVS2_DNC_3 : 32|32@1+ (1,0) [0|0] "" Vector__XXX
 SG_ CCVS2_DNC_1 : 6|2@1+ (1,0) [0|3] "" Vector__XXX
 SG_ CCVS2_DNC_2 : 8|24@1+ (1,0) [0|16777215] "" Vector__XXX
 SG_ CruiseCtrlPauseCmd : 4|2@1+ (1,0) [0|3] "" Vector__XXX
 SG_ CruiseCtrlResumeCmd : 2|2@1+ (1,0) [0|3] "" Vector__XXX
 SG_ CruiseCtrlDisableCmd : 0|2@1+ (1,0) [0|3] "" Vector__XXX

BO_ 2364549379 SSI2: 8 Vector__XXX
 SG_ SSI2_RollAngleMerit : 54|2@1+ (1,0) [0|3] "bit" Vector__XXX
 SG_ SSI2_RollAngleCompensation : 52|2@1+ (1,0) [0|3] "bit" Vector__XXX
 SG_ SSI2_RollAngle : 24|24@1+ (3.0517578125E-005,-250) [-250|252] "deg" Vector__XXX
 SG_ SSI2_RollAndPitchLatency : 56|8@1+ (0.5,0) [0|125] "ms" Vector__XXX
 SG_ SSI2_PitchAngleMerit : 50|2@1+ (1,0) [0|3] "bit" Vector__XXX
 SG_ SSI2_PitchAngleCompensation : 48|2@1+ (1,0) [0|3] "bit" Vector__XXX
 SG_ SSI2_PitchAngle : 0|24@1+ (3.0517578125E-005,-250) [-250|252] "deg" Vector__XXX

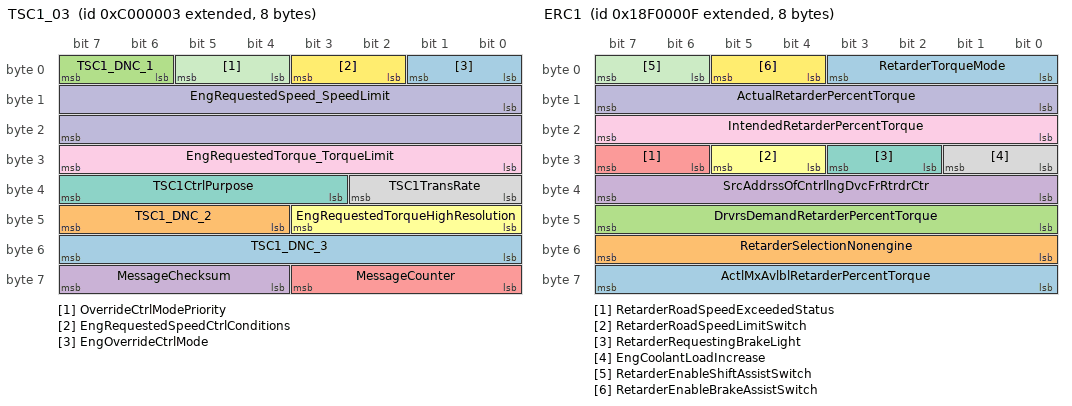
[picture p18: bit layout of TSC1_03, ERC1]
BO_ 2348810243 TSC1_03: 8 Vector__XXX
 SG_ TSC1_DNC_3 : 48|8@1+ (1,0) [0|255] "" Vector__XXX
 SG_ TSC1_DNC_2 : 44|4@1+ (1,0) [0|15] "" Vector__XXX
 SG_ TSC1_DNC_1 : 6|2@1+ (1,0) [0|3] "" Vector__XXX
 SG_ MessageChecksum : 60|4@1+ (1,0) [0|15] "" Vector__XXX
 SG_ MessageCounter : 56|4@1+ (1,0) [0|15] "" Vector__XXX
 SG_ EngRequestedTorqueHighResolution : 40|4@1+ (0.125,0) [0|1.875] "%" Vector__XXX
 SG_ TSC1CtrlPurpose : 35|5@1+ (1,0) [0|31] "" Vector__XXX
 SG_ TSC1TransRate : 32|3@1+ (1,0) [0|7] "" Vector__XXX
 SG_ EngRequestedTorque_TorqueLimit : 24|8@1+ (1,-125) [-125|125] "%" Vector__XXX
 SG_ EngRequestedSpeed_SpeedLimit : 8|16@1+ (0.125,0) [0|8031.875] "rpm" Vector__XXX
 SG_ OverrideCtrlModePriority : 4|2@1+ (1,0) [0|3] "" Vector__XXX
 SG_ EngRequestedSpeedCtrlConditions : 2|2@1+ (1,0) [0|3] "" Vector__XXX
 SG_ EngOverrideCtrlMode : 0|2@1+ (1,0) [0|3] "" Vector__XXX

BO_ 2565865487 ERC1: 8 Vector__XXX
 SG_ ActlMxAvlblRetarderPercentTorque : 56|8@1+ (1,-125) [-125|0] "%" Vector__XXX
 SG_ RetarderSelectionNonengine : 48|8@1+ (0.4,0) [0|100] "%" Vector__XXX
 SG_ DrvrsDemandRetarderPercentTorque : 40|8@1+ (1,-125) [-125|0] "%" Vector__XXX
 SG_ SrcAddrssOfCntrllngDvcFrRtrdrCtr : 32|8@1+ (1,0) [0|253] "" Vector__XXX
 SG_ RetarderRoadSpeedExceededStatus : 30|2@1+ (1,0) [0|3] "" Vector__XXX
 SG_ RetarderRoadSpeedLimitSwitch : 28|2@1+ (1,0) [0|3] "" Vector__XXX
 SG_ RetarderRequestingBrakeLight : 26|2@1+ (1,0) [0|3] "" Vector__XXX
 SG_ EngCoolantLoadIncrease : 24|2@1+ (1,0) [0|3] "" Vector__XXX
 SG_ IntendedRetarderPercentTorque : 16|8@1+ (1,-125) [-125|0] "%" Vector__XXX
 SG_ ActualRetarderPercentTorque : 8|8@1+ (1,-125) [-125|0] "%" Vector__XXX
 SG_ RetarderEnableShiftAssistSwitch : 6|2@1+ (1,0) [0|3] "" Vector__XXX
 SG_ RetarderEnableBrakeAssistSwitch : 4|2@1+ (1,0) [0|3] "" Vector__XXX
 SG_ RetarderTorqueMode : 0|4@1+ (1,0) [0|15] "" Vector__XXX

BA_DEF_ SG_  "SigType" ENUM  "Default","Range","RangeSigned","ASCII","Discrete","Control","ReferencePGN","DTC","StringDelimiter","StringLength","StringLengthControl","MessageCounter","MessageChecksum";
BA_DEF_ SG_  "GenSigEVName" STRING ;
BA_DEF_ SG_  "GenSigILSupport" ENUM  "No","Yes";
BA_DEF_ SG_  "GenSigSendType" ENUM  "Cyclic","OnWrite","OnWriteWithRepetition","OnChange","OnChangeWithRepetition","IfActive","IfActiveWithRepetition","NoSigSendType";
BA_DEF_ BO_  "GenMsgILSupport" ENUM  "No","Yes";
BA_DEF_ BU_  "NmStationAddress" INT 0 255;
BA_DEF_ BO_  "GenMsgSendType" ENUM  "cyclic","NotUsed","IfActive","NotUsed","NotUsed","NotUsed","NotUsed","NotUsed","noMsgSendType";
BA_DEF_ BO_  "GenMsgRequestable" INT 0 1;
BA_DEF_  "DBName" STRING ;
BA_DEF_  "BusType" STRING ;
BA_DEF_  "ProtocolType" STRING ;
BA_DEF_ BO_  "VFrameFormat" ENUM  "StandardCAN","ExtendedCAN","reserved","J1939PG";
BA_DEF_DEF_  "SigType" "Default";
BA_DEF_DEF_  "GenSigEVName" "Env@Nodename_@Signame";
BA_DEF_DEF_  "GenSigILSupport" "Yes";
BA_DEF_DEF_  "GenSigSendType" "NoSigSendType";
BA_DEF_DEF_  "GenMsgILSupport" "Yes";
BA_DEF_DEF_  "NmStationAddress" 254;
BA_DEF_DEF_  "GenMsgSendType" "noMsgSendType";
BA_DEF_DEF_  "GenMsgRequestable" 1;
BA_DEF_DEF_  "DBName" "";
BA_DEF_DEF_  "BusType" "CAN";
BA_DEF_DEF_  "ProtocolType" "J1939";
BA_DEF_DEF_  "VFrameFormat" "J1939PG";
BA_ "DBName" "Truck_Messages";
